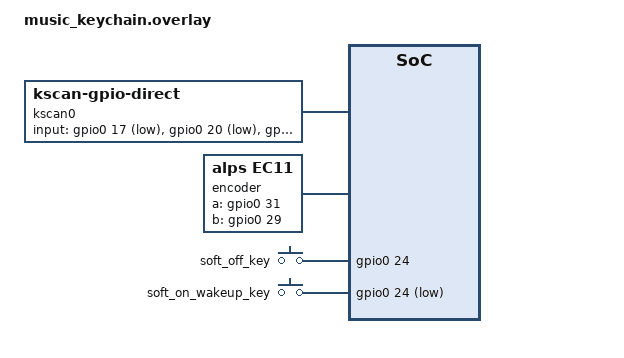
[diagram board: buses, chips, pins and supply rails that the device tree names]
/*
 * Final hardware GPIO map, reported from the labels printed on the board:
 *
 * PIN_PREVIOUS_TRACK = P0.17
 * PIN_PLAY_PAUSE     = P0.20
 * PIN_NEXT_TRACK     = P0.22
 * PIN_ENCODER_A      = P0.31 (top rotation pin)
 * PIN_ENCODER_B      = P0.29 (bottom rotation pin)
 * PIN_SOFT_POWER     = P0.24 (maintained switch; other terminal to GND)
 *
 * All controls are active-low and share GND. These use the nRF52840's gpio0
 * controller directly, so the numbers are raw P0.xx GPIO numbers.
 */

#include <dt-bindings/zmk/matrix_transform.h>

/ {
    chosen {
        zmk,kscan = &kscan0;
        zmk,matrix-transform = &default_transform;
    };

    default_transform: keymap_transform_0 {
        compatible = "zmk,matrix-transform";
        columns = <3>;
        rows = <1>;
        map = <RC(0, 0) RC(0, 1) RC(0, 2)>;
    };

    kscan0: kscan {
        compatible = "zmk,kscan-gpio-direct";
        wakeup-source;
        debounce-press-ms = <10>;
        debounce-release-ms = <10>;
        input-gpios
            = <&gpio0 17 (GPIO_ACTIVE_LOW | GPIO_PULL_UP)> /* PIN_PREVIOUS_TRACK */
            , <&gpio0 20 (GPIO_ACTIVE_LOW | GPIO_PULL_UP)> /* PIN_PLAY_PAUSE */
            , <&gpio0 22 (GPIO_ACTIVE_LOW | GPIO_PULL_UP)> /* PIN_NEXT_TRACK */
            ;
    };

    encoder: encoder {
        compatible = "alps,ec11";
        a-gpios = <&gpio0 31 (GPIO_ACTIVE_HIGH | GPIO_PULL_UP)>; /* PIN_ENCODER_A */
        b-gpios = <&gpio0 29 (GPIO_ACTIVE_HIGH | GPIO_PULL_UP)>; /* PIN_ENCODER_B */
        /* Provisional EC11 value; tune after a hardware rotation test. */
        steps = <80>;
        status = "okay";
    };

    sensors: sensors {
        compatible = "zmk,keymap-sensors";
        sensors = <&encoder>;
        /* About eight volume events per turn: roughly two turns, 0 to max. */
        triggers-per-rotation = <8>;
    };

    /* Maintained soft-power switch: one terminal to GND, the other to P0.24. */
    soft_power_keys {
        compatible = "gpio-keys";

        /* Open means OFF. The pull-up makes the open state active-high. */
        soft_off_key: soft_off_key {
            gpios = <&gpio0 24 (GPIO_ACTIVE_HIGH | GPIO_PULL_UP)>;
        };

        /* Closed to GND means ON and is the active-low wake condition. */
        soft_on_wakeup_key: soft_on_wakeup_key {
            gpios = <&gpio0 24 (GPIO_ACTIVE_LOW | GPIO_PULL_UP)>;
        };
    };

    behaviors {
        immediate_soft_off: immediate_soft_off {
            compatible = "zmk,behavior-immediate-soft-off";
            #binding-cells = <0>;
        };
    };

    soft_power_scan: soft_power_scan {
        compatible = "zmk,kscan-gpio-direct";
        input-keys = <&soft_off_key>;
        wakeup-source;
        debounce-press-ms = <20>;
        debounce-release-ms = <20>;
    };

    soft_power_sideband {
        compatible = "zmk,kscan-sideband-behaviors";
        kscan = <&soft_power_scan>;
        auto-enable;
        wakeup-source;

        turn_off_immediately {
            row = <0>;
            column = <0>;
            bindings = <&immediate_soft_off>;
        };
    };

    /* During soft-off, closing the switch grounds P0.24 and wakes the board. */
    soft_power_wakeup: soft_power_wakeup {
        compatible = "zmk,gpio-key-wakeup-trigger";
        trigger = <&soft_on_wakeup_key>;
        wakeup-source;
    };

    soft_off_wakers {
        compatible = "zmk,soft-off-wakeup-sources";
        wakeup-sources = <&soft_power_wakeup>;
    };
};

